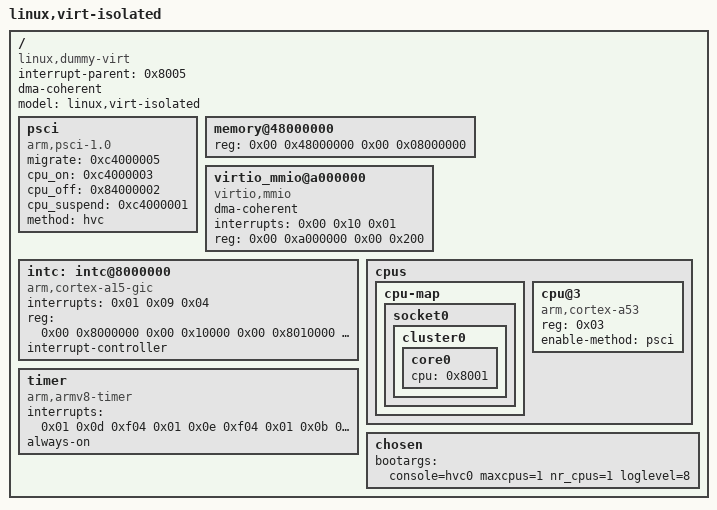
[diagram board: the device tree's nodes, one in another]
/dts-v1/;

/ {
    interrupt-parent = <0x8005>;
    dma-coherent;
    model = "linux,virt-isolated";
    compatible = "linux,dummy-virt";
    #address-cells = <0x02>;
    #size-cells = <0x02>;

    psci {
        migrate = <0xc4000005>;
        cpu_on = <0xc4000003>;
        cpu_off = <0x84000002>;
        cpu_suspend = <0xc4000001>;
        method = "hvc";
        compatible = "arm,psci-1.0", "arm,psci-0.2", "arm,psci";
    };

    memory@48000000 {
        device_type = "memory";
        reg = <0x00 0x48000000 0x00 0x08000000>;
    };

    virtio_mmio@a000000 {
        dma-coherent;
        interrupts = <0x00 0x10 0x01>;
        reg = <0x00 0xa000000 0x00 0x200>;
        compatible = "virtio,mmio";
    };

    intc: intc@8000000 {
        phandle = <0x8005>;
        interrupts = <0x01 0x09 0x04>;
        reg = <0x00 0x8000000 0x00 0x10000 0x00 0x8010000 0x00 0x10000 0x00 0x8030000 0x00 0x10000 0x00 0x8040000 0x00 0x10000>;
        compatible = "arm,cortex-a15-gic";
        ranges;
        #size-cells = <0x02>;
        #address-cells = <0x02>;
        interrupt-controller;
        #interrupt-cells = <0x03>;
    };

    cpus {
        #size-cells = <0x00>;
        #address-cells = <0x01>;

        cpu-map {
            socket0 {
                cluster0 {
                    core0 { cpu = <0x8001>; };
                };
            };
        };

        cpu@3 {
            phandle = <0x8001>;
            reg = <0x03>;
            enable-method = "psci";
            compatible = "arm,cortex-a53";
            device_type = "cpu";
        };
    };

    timer {
        interrupts = <0x01 0x0d 0xf04 0x01 0x0e 0xf04 0x01 0x0b 0xf04 0x01 0x0a 0xf04>;
        always-on;
        compatible = "arm,armv8-timer", "arm,armv7-timer";
    };

    chosen {
        bootargs = "console=hvc0 maxcpus=1 nr_cpus=1 loglevel=8";
    };
};
